# CY8C4245AXI_483 register map
File version: 0.1
PSoC 4200
Registers are 32-bit, read-write, no defined reset value unless marked. A register's access mark holds for its fields unless they carry their own. Offsets are from the block's base; lines under a group give offsets from that group; [hi:lo] are bit positions; {n}, {i} and the like mark numbered series; 'fields as' and 'values as' point back to an identical list; <NAME> marks a mode.

## Memory map
0x00000000 uStepTimer
0x00000000 ADC_SAR_Seq_1 — Sequencing SAR ADC
0x00000000 PWM_A
0x00000000 PWM_B
0x00000000 Opamp_B — OpAmp
0x00000000 Opamp_A — OpAmp
0x00000000 IDAC_A — IDAC
0x00000000 IDAC_B — IDAC
0x00000000 mbPortTimer
0x00000000 SCB — Serial Communication Block
0x00000000 SPI — Serial Communication Block
0x400F0071 ControlReg
0x400F0072 ControlEnable

## uStepTimer
Base 0x00000000
0x400F0000 uStepTimer_COUNTER — UDB.A0 - Current Down Counter Value
0x400F0020 uStepTimer_PERIOD — UDB.D0 - Assigned Period
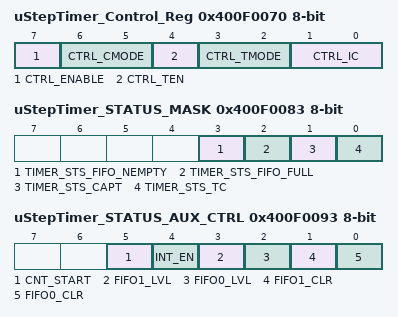
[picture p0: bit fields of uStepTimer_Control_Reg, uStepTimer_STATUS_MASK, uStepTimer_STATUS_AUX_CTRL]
0x400F0070 uStepTimer_Control_Reg 8-bit — UDB Control Register - Assigned Control Register Value
  [7] CTRL_ENABLE — Enable the Timer
  [6:5] CTRL_CMODE — Capture Mode
  [4] CTRL_TEN — Trigger Enable Bit
  [3:2] CTRL_TMODE — Trigger Mode
  [1:0] CTRL_IC — Interrupt Count
0x400F0083 uStepTimer_STATUS_MASK 8-bit — UDB Status bits Interrupt Mask Enable Register
  [3] TIMER_STS_FIFO_NEMPTY ro — FIFO Empty status
  [2] TIMER_STS_FIFO_FULL ro — FIFO Full Status
  [1] TIMER_STS_CAPT ro — Enables the Interrupt on Capture
  [0] TIMER_STS_TC ro — Enables the Interrupt on TC
0x400F0093 uStepTimer_STATUS_AUX_CTRL 8-bit — UDB Auxilliary Control Register
  [5] CNT_START — FIFO0 clear
    0=E_CNT_START0 (Disable counter); 1=E_CNT_START1 (Enable counter)
  [4] INT_EN
    0=E_INT_EN0 (Interrupt disabled); 1=E_INT_EN1 (Interrupt enabled)
  [3] FIFO1_LVL — FIFO level
    0=E_FIFO_LVL_0 (FIFO LVL: input mode: FIFO not full; output mode: FIFO not empty); 1=E_FIFO_LVL_1 (FIFO LVL: input mode: FIFO at least 1/2 empty; output mode: FIFO at least 1/2 full)
  [2] FIFO0_LVL — FIFO level
    values as FIFO1_LVL
  [1] FIFO1_CLR — FIFO1 clear
    0=E_FIFO_CLR_0 (Normal FIFO operation); 1=E_FIFO_CLR_1 (Clear FIFO state)
  [0] FIFO0_CLR — FIFO0 clear
    values as FIFO1_CLR

## ControlEnable
Base 0x400F0072
0x00 ControlEnable_CONTROL_REG 8-bit

## ControlReg
Base 0x400F0071
Registers as ControlEnable (with ControlEnable read as ControlReg).

## PWM_A
Base 0x00000000
0x40050148 COUNTER — Current counter value
0x4005014C CC — Compare / capture value
0x40050150 CC_BUF — Compare / capture buffer value
0x40050154 PERIOD — Period value
0x40050158 PERIOD_BUF — Period buffer value

## PWM_B
Base 0x00000000
0x40050108 COUNTER — Current counter value
0x4005010C CC — Compare / capture value
0x40050110 CC_BUF — Compare / capture buffer value
0x40050114 PERIOD — Period value
0x40050118 PERIOD_BUF — Period buffer value

## Opamp_B — OpAmp
Base 0x00000000
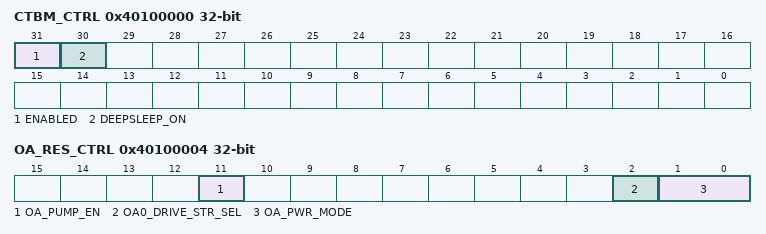
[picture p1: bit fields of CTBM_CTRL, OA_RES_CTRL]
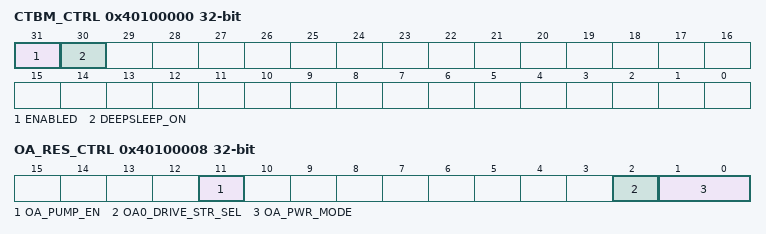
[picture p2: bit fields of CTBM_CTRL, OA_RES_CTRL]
0x40100000 CTBM_CTRL — Global CTB IP and power control
  [31] ENABLED — Selects component behavior in DeepSleep power mode
    0=DISABLE (CTB IP disabled (put analog in power down, open all switches)); 1=ENABLE (CTB IP enabledCTB IP enabled)
  [30] DEEPSLEEP_ON — Selects component behavior in DeepSleep power mode
    0=DISABLE (CTB IP disabled off during DeepSleep power mode); 1=ENABLE (CTB IP remains enabled during DeepSleep power mode (if ENABLED=1))
0x40100004 OA_RES_CTRL — Opamp and resistor control
  [11] OA_PUMP_EN — Selects pump
    0=DISABLE (Pump disabled); 1=ENABLE (Pump enabled)
  [2] OA0_DRIVE_STR_SEL — Opamp output strenght select
    0=Cy1x (Internal only); 1=Cy10x (Output to pin)
  [1:0] OA_PWR_MODE — Selects power for opamp
    0=OFF; 1=LOW (Low power); 2=MED (Medium power); 3=HIGH (High power)
0x40100F08 OA_COMP_TRIM — Opamp Compenation Capacitor Trim
  [1:0] OA_COMP_TRIM
    1=HIGH_SPEED; 2=BALANCED; 3=HIGH_STABILITY

## Opamp_A — OpAmp
Base 0x00000000
0x40100000 CTBM_CTRL — Global CTB IP and power control
  [31] ENABLED — Selects component behavior in DeepSleep power mode
    0=DISABLE (CTB IP disabled (put analog in power down, open all switches)); 1=ENABLE (CTB IP enabledCTB IP enabled)
  [30] DEEPSLEEP_ON — Selects component behavior in DeepSleep power mode
    0=DISABLE (CTB IP disabled off during DeepSleep power mode); 1=ENABLE (CTB IP remains enabled during DeepSleep power mode (if ENABLED=1))
0x40100008 OA_RES_CTRL — Opamp and resistor control
  [11] OA_PUMP_EN — Selects pump
    0=DISABLE (Pump disabled); 1=ENABLE (Pump enabled)
  [2] OA0_DRIVE_STR_SEL — Opamp output strenght select
    0=Cy1x (Internal only); 1=Cy10x (Output to pin)
  [1:0] OA_PWR_MODE — Selects power for opamp
    0=OFF; 1=LOW (Low power); 2=MED (Medium power); 3=HIGH (High power)
0x40100F14 OA_COMP_TRIM — Opamp Compenation Capacitor Trim
  [1:0] OA_COMP_TRIM
    1=HIGH_SPEED; 2=BALANCED; 3=HIGH_STABILITY
